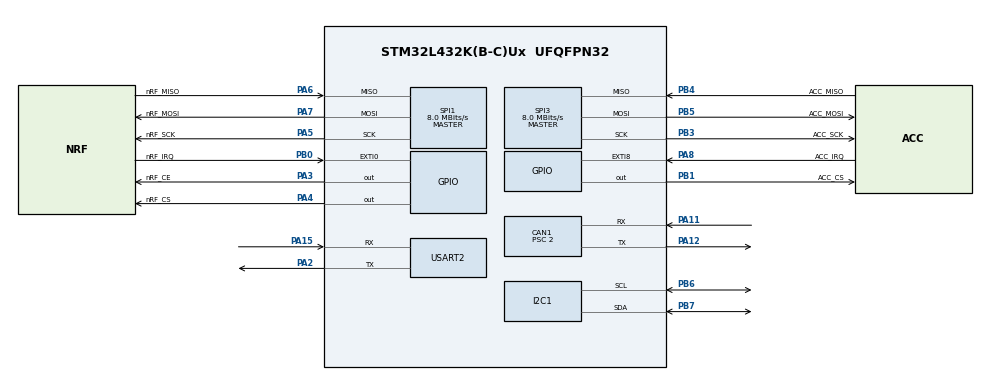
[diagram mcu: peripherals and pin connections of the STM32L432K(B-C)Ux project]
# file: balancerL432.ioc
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CAN1.BS1=CAN_BS1_7TQ
CAN1.BS2=CAN_BS2_8TQ
CAN1.CalculateBaudRate=500000
CAN1.CalculateTimeBit=2000
CAN1.CalculateTimeQuantum=125.0
CAN1.Mode=CAN_MODE_LOOPBACK
CAN1.Prescaler=2
FREERTOS.Tasks01=defaultTask,24,128,StartDefaultTask,Default,NULL,Dynamic,NULL,NULL
FREERTOS.configUSE_NEWLIB_REENTRANT=1
I2C1.Timing=0x00503D58
Mcu.Family=STM32L4
Mcu.Name=STM32L432K(B-C)Ux
Mcu.Package=UFQFPN32
NVIC.CAN1_RX0_IRQn=true\:5\:0\:false\:false\:true\:true\:true\:true\:true
NVIC.CAN1_RX1_IRQn=true\:5\:0\:false\:false\:true\:true\:true\:true\:true
NVIC.EXTI0_IRQn=true\:5\:0\:false\:false\:true\:true\:true\:true\:true
NVIC.EXTI9_5_IRQn=true\:5\:0\:false\:false\:true\:true\:true\:true\:true
NVIC.PriorityGroup=NVIC_PRIORITYGROUP_4
NVIC.TIM6_DAC_IRQn=true\:15\:0\:false\:false\:true\:false\:false\:true\:true
NVIC.TimeBase=TIM6_DAC_IRQn
NVIC.TimeBaseIP=TIM6
PA0.Signal=ADCx_IN5
PA1.Signal=ADCx_IN6
PA10.Signal=USART1_RX
PA11.Mode=CAN_Activate
PA11.Signal=CAN1_RX
PA12.Mode=CAN_Activate
PA12.Signal=CAN1_TX
PA13\ (JTMS-SWDIO).Mode=Serial_Wire
PA13\ (JTMS-SWDIO).Signal=SYS_JTMS-SWDIO
PA14\ (JTCK-SWCLK).Mode=Serial_Wire
PA14\ (JTCK-SWCLK).Signal=SYS_JTCK-SWCLK
PA15\ (JTDI).Mode=Asynchronous
PA15\ (JTDI).Signal=USART2_RX
PA2.Mode=Asynchronous
PA2.Signal=USART2_TX
PA3.GPIO_Label=nRF_CE
PA3.Signal=GPIO_Output
PA4.GPIO_Label=nRF_CS
PA4.Signal=GPIO_Output
PA5.GPIO_Label=nRF_SCK
PA5.Mode=Full_Duplex_Master
PA5.Signal=SPI1_SCK
PA6.GPIO_Label=nRF_MISO
PA6.Mode=Full_Duplex_Master
PA6.Signal=SPI1_MISO
PA7.GPIO_Label=nRF_MOSI
PA7.Mode=Full_Duplex_Master
PA7.Signal=SPI1_MOSI
PA8.GPIO_Label=ACC_IRQ
PA8.Signal=GPXTI8
PA9.Signal=USART1_TX
PB0.GPIO_Label=nRF_IRQ
PB0.Signal=GPXTI0
PB1.GPIO_Label=ACC_CS
PB1.Signal=GPIO_Output
PB3\ (JTDO-TRACESWO).GPIO_Label=ACC_SCK
PB3\ (JTDO-TRACESWO).Mode=Full_Duplex_Master
PB3\ (JTDO-TRACESWO).Signal=SPI3_SCK
PB4\ (NJTRST).GPIO_Label=ACC_MISO
PB4\ (NJTRST).Mode=Full_Duplex_Master
PB4\ (NJTRST).Signal=SPI3_MISO
PB5.GPIO_Label=ACC_MOSI
PB5.Mode=Full_Duplex_Master
PB5.Signal=SPI3_MOSI
PB6.Mode=I2C
PB6.Signal=I2C1_SCL
PB7.Mode=I2C
PB7.Signal=I2C1_SDA
ProjectManager.HeapSize=0x200
ProjectManager.StackSize=0x400
ProjectManager.TargetToolchain=STM32CubeIDE
RCC.ADCFreq_Value=64000000
RCC.AHBFreq_Value=16000000
RCC.APB1Freq_Value=16000000
RCC.APB1TimFreq_Value=16000000
RCC.APB2Freq_Value=16000000
RCC.APB2TimFreq_Value=16000000
RCC.CortexFreq_Value=16000000
RCC.HCLKFreq_Value=16000000
RCC.HSE_VALUE=8000000
RCC.HSI48_VALUE=48000000
RCC.HSI_VALUE=16000000
RCC.LSE_VALUE=32768
RCC.MSI_VALUE=4000000
RCC.PLLSourceVirtual=RCC_PLLSOURCE_HSI
RCC.SYSCLKFreq_VALUE=16000000
RCC.SYSCLKSource=RCC_SYSCLKSOURCE_HSI
RCC.USBFreq_Value=64000000
RCC.VCOOutputFreq_Value=128000000
SH.ADCx_IN5.0=ADC1_IN5
SH.ADCx_IN6.0=ADC1_IN6
SPI1.CalculateBaudRate=8.0 MBits/s
SPI1.Direction=SPI_DIRECTION_2LINES
SPI1.Mode=SPI_MODE_MASTER
SPI1.VirtualType=VM_MASTER
SPI3.CalculateBaudRate=8.0 MBits/s
SPI3.Direction=SPI_DIRECTION_2LINES
SPI3.Mode=SPI_MODE_MASTER
SPI3.VirtualType=VM_MASTER
USART2.VirtualMode-Asynchronous=VM_ASYNC
VP_FREERTOS_VS_CMSIS_V2.Mode=CMSIS_V2
VP_SYS_VS_tim6.Mode=TIM6
board=custom

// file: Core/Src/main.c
/* USER CODE BEGIN Header */
/**
  ******************************************************************************
  * @file           : main.c
  * @brief          : Main program body
  ******************************************************************************
  * @attention
  *
  * Copyright (c) 2026 STMicroelectronics.
  * All rights reserved.
  *
  * This software is licensed under terms that can be found in the LICENSE file
  * in the root directory of this software component.
  * If no LICENSE file comes with this software, it is provided AS-IS.
  *
  ******************************************************************************
  */
/* USER CODE END Header */
#include "main.h"
#include "cmsis_os.h"
#include "can.h"
#include "i2c.h"
#include "spi.h"
#include "usart.h"
#include "gpio.h"

/* USER CODE BEGIN Includes */
#include "../../../mmnrf24lib/nrf24.h"
/* USER CODE END Includes */

void SystemClock_Config(void);
void MX_FREERTOS_Init(void);

int main(void)
{

  /* MCU Configuration--------------------------------------------------------*/

  /* Reset of all peripherals, Initializes the Flash interface and the Systick. */
  HAL_Init();

  /* Configure the system clock */
  SystemClock_Config();

  /* Initialize all configured peripherals */
  MX_GPIO_Init();
  MX_CAN1_Init();
  MX_I2C1_Init();
  MX_SPI1_Init();
  MX_SPI3_Init();
  MX_USART2_UART_Init();
  /* USER CODE BEGIN 2 */
  can_start_motor_srv();

  nrf24_init(nRF24_ROLE_PERIPHERIAL);
  nrf24_open();

  /* USER CODE END 2 */

  /* Init scheduler */
  osKernelInitialize();  /* Call init function for freertos objects (in cmsis_os2.c) */
  MX_FREERTOS_Init();

  /* Start scheduler */
  osKernelStart();

  /* We should never get here as control is now taken by the scheduler */

  /* Infinite loop */
  while (1)
  {

  }
}

void SystemClock_Config(void)
{
  LL_FLASH_SetLatency(LL_FLASH_LATENCY_0);
  while(LL_FLASH_GetLatency()!= LL_FLASH_LATENCY_0)
  {
  }
  LL_PWR_SetRegulVoltageScaling(LL_PWR_REGU_VOLTAGE_SCALE1);
  while (LL_PWR_IsActiveFlag_VOS() != 0)
  {
  }
  LL_RCC_HSI_Enable();

   /* Wait till HSI is ready */
  while(LL_RCC_HSI_IsReady() != 1)
  {

  }
  LL_RCC_HSI_SetCalibTrimming(16);
  LL_RCC_SetSysClkSource(LL_RCC_SYS_CLKSOURCE_HSI);

   /* Wait till System clock is ready */
  while(LL_RCC_GetSysClkSource() != LL_RCC_SYS_CLKSOURCE_STATUS_HSI)
  {

  }
  LL_RCC_SetAHBPrescaler(LL_RCC_SYSCLK_DIV_1);
  LL_RCC_SetAPB1Prescaler(LL_RCC_APB1_DIV_1);
  LL_RCC_SetAPB2Prescaler(LL_RCC_APB2_DIV_1);
  LL_SetSystemCoreClock(16000000);

   /* Update the time base */
  if (HAL_InitTick (TICK_INT_PRIORITY) != HAL_OK)
  {
    Error_Handler();
  }
}

void HAL_TIM_PeriodElapsedCallback(TIM_HandleTypeDef *htim)
{
  if (htim->Instance == TIM6)
  {
    HAL_IncTick();
  }
}

void Error_Handler(void)
{
  __disable_irq();
  while (1)
  {
  }
}
